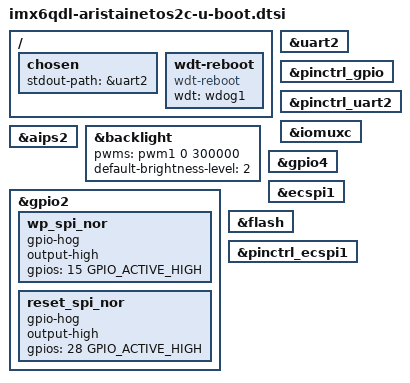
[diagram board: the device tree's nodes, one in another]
// SPDX-License-Identifier: GPL-2.0+ or X11
/*
 * Copyright (C) 2019 Heiko Schocher <hs@denx.de>
 */

/ {
	chosen {
		bootph-all;
		stdout-path = &uart2;
	};

	wdt-reboot {
		compatible = "wdt-reboot";
		wdt = <&wdog1>;
	};
};

&uart2 {
	bootph-all;
};

&pinctrl_gpio {
	bootph-all;
};

&pinctrl_uart2 {
	bootph-all;
};

&iomuxc {
	bootph-all;
};

&aips2 {
	bootph-all;
};

&backlight {
	pwms = <&pwm1 0 300000>;
	default-brightness-level = <2>;
};

/*
 * allow switching write protect / reset pin by gpio,
 * because "pinctrl-assert-gpios" from &ecspi1 isn't handled by u-boot
 */
&gpio2 {
	bootph-all;

	wp_spi_nor {
		gpio-hog;
		output-high;
		gpios = <15 GPIO_ACTIVE_HIGH>;
	};

	reset_spi_nor {
		gpio-hog;
		output-high;
		gpios = <28 GPIO_ACTIVE_HIGH>;
	};
};

&gpio4 {
	bootph-all;
};

&ecspi1 {
	bootph-all;
};

&flash {
	bootph-all;
};

&pinctrl_ecspi1 {
	bootph-all;
};
